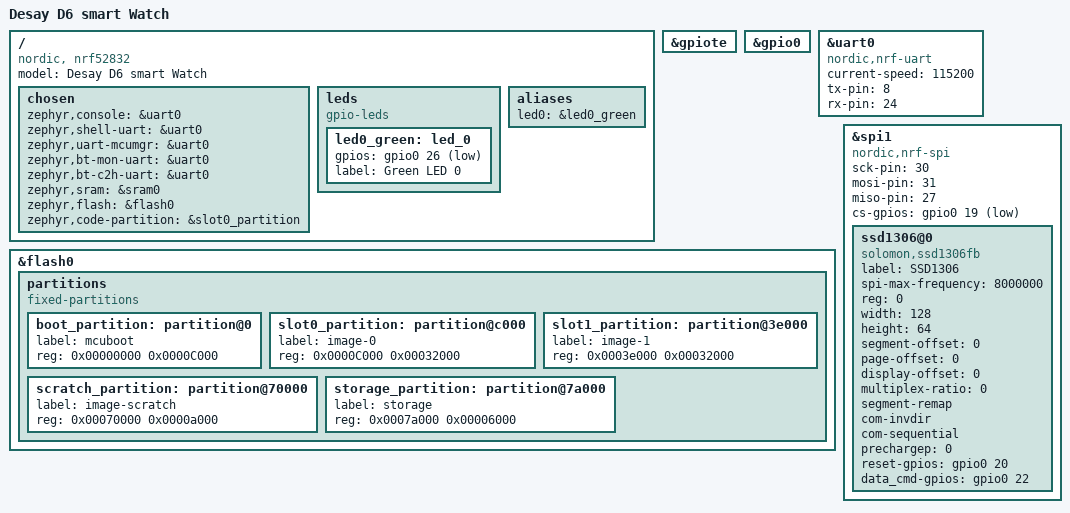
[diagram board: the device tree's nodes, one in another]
/*
 * Copyright (c) 2019 Nordic Semiconductor ASA
 *
 * SPDX-License-Identifier: LicenseRef-BSD-5-Clause-Nordic
 */

/dts-v1/;
#include <nordic/nrf52832_qfaa.dtsi>

/ {
	model = "Desay D6 smart Watch";
	compatible = "nordic, nrf52832";

	chosen {
		zephyr,console = &uart0;
                zephyr,shell-uart = &uart0;
                zephyr,uart-mcumgr = &uart0;
                zephyr,bt-mon-uart = &uart0;
                zephyr,bt-c2h-uart = &uart0;

		zephyr,sram = &sram0;
		zephyr,flash = &flash0;
		zephyr,code-partition = &slot0_partition;
	};
        leds    {
                compatible = "gpio-leds";
                led0_green: led_0 {
/*pin 25 is the motor*/
/*use this to power OLED*/
                       //gpios = <&gpio0 8 GPIO_ACTIVE_LOW>; //soldered test contact
                     //  gpios = <&gpio0 24 GPIO_ACTIVE_LOW>;
                       gpios = <&gpio0 26 GPIO_ACTIVE_LOW>;
                       label = "Green LED 0";
                };

         };





	aliases {
		led0 = &led0_green;

	};

};

&gpiote {
	status = "okay";
};

&gpio0 {
	status = "okay";
};
&uart0 {
	status = "okay";
	compatible = "nordic,nrf-uart";
	current-speed = <115200>;
	tx-pin = <8>;
	rx-pin = <24>;
};


&flash0 {
	/*
	 * For more information, see:
	 * http://docs.zephyrproject.org/latest/guides/dts/index.html#flash-partitions
	 */
	partitions {
		compatible = "fixed-partitions";
		#address-cells = <1>;
		#size-cells = <1>;

		boot_partition: partition@0 {
			label = "mcuboot";
			reg = <0x00000000 0x0000C000>;
		};
		slot0_partition: partition@c000 {
			label = "image-0";
			reg = <0x0000C000 0x00032000>;
		};
		slot1_partition: partition@3e000 {
			label = "image-1";
			reg = <0x0003e000 0x00032000>;
		};
		scratch_partition: partition@70000 {
			label = "image-scratch";
			reg = <0x00070000 0x0000a000>;
		};
		storage_partition: partition@7a000 {
			label = "storage";
			reg = <0x0007a000 0x00006000>;
		};
	};
};



&spi1 {
        compatible = "nordic,nrf-spi";
        status = "okay";
        sck-pin = <30>;
        mosi-pin = <31>;
        miso-pin = <27>;
        //cs-gpios = <&gpio0 26 GPIO_ACTIVE_LOW>, <&gpio0 19 GPIO_ACTIVE_LOW>; //only first gets set
        cs-gpios = <&gpio0 19  GPIO_ACTIVE_LOW>;
       // cs-gpios = <&gpio0 5 GPIO_ACTIVE_LOW>; //goran mahovlic
        ssd1306@0 {
                compatible = "solomon,ssd1306fb";
                label = "SSD1306";
                spi-max-frequency = <8000000>; 
                reg = <0>;
		width = <128>;
		height = <64>;
		segment-offset = <0>;
		page-offset = <0>;
		display-offset = <0>; 
		multiplex-ratio = <0>;
		segment-remap;
		com-invdir;
		com-sequential;
		//prechargep = <0x00>;
		prechargep = <0>;
		reset-gpios = <&gpio0 20 0>;
                data_cmd-gpios = <&gpio0 22 0>;
        };
};

